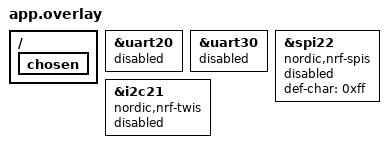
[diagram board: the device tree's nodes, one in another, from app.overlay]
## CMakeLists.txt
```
cmake_minimum_required(VERSION 3.20.0)
find_package(Zephyr REQUIRED HINTS $ENV{ZEPHYR_BASE})
project(r01_serial LANGUAGES C CXX)
target_sources(app PRIVATE src/main.cpp)
```

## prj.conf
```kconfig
CONFIG_ZTEST=y
CONFIG_CPP=y
CONFIG_STD_CPP17=y
CONFIG_CPP_EXCEPTIONS=n
CONFIG_CPP_RTTI=n
CONFIG_ZTEST_NO_YIELD=y
CONFIG_CONSOLE=n
CONFIG_SERIAL=n
CONFIG_PRINTK=n
CONFIG_LOG=n
CONFIG_NUCODE_ARDUINO_CORE=y
CONFIG_NUCODE_ARDUINO_RUNTIME=n
CONFIG_NUCODE_ARDUINO_API=y
CONFIG_NUCODE_ARDUINO_IO_OWNERSHIP=y
CONFIG_NUCODE_ARDUINO_IO_RESOURCE_SLOTS=64
CONFIG_NUCODE_ARDUINO_GPIO=y
CONFIG_NUCODE_ARDUINO_CONNECTOR_GPIO=y
CONFIG_NUCODE_ARDUINO_DAP_UART_GPIO_PINS=y
CONFIG_NUCODE_ARDUINO_INTERRUPTS=n
CONFIG_NUCODE_ARDUINO_TIME=n
CONFIG_NUCODE_ARDUINO_SERIAL=n
CONFIG_NUCODE_ARDUINO_SERIAL_FABRIC=y
CONFIG_NUCODE_ARDUINO_WIRE=n
CONFIG_NUCODE_ARDUINO_SPI=n
CONFIG_NUCODE_ARDUINO_ADC=n
CONFIG_NUCODE_ARDUINO_PWM=n
CONFIG_COMMON_LIBC_MALLOC_ARENA_SIZE=8192
CONFIG_MAIN_STACK_SIZE=4096
CONFIG_TEST_EXTRA_STACK_SIZE=2048
```

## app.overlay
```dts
/** @brief 직접 adapter의 IRQ를 Zephyr device가 소유하지 않는 구성입니다. */
#include <nucode/nu54dk-arduino-pins.dtsi>

/ {
    chosen {
        /delete-property/ zephyr,console;
        /delete-property/ zephyr,shell-uart;
        /delete-property/ zephyr,uart-mcumgr;
        /delete-property/ zephyr,bt-mon-uart;
        /delete-property/ zephyr,bt-c2h-uart;
    };
};

&uart20 { status = "disabled"; };
&uart30 { status = "disabled"; };

/** @brief nrfx의 compatible 조건만 제공하고 device와 IRQ는 비활성으로 유지합니다. */
&spi22 {
    compatible = "nordic,nrf-spis";
    /delete-property/ rx-delay-supported;
    /delete-property/ rx-delay;
    def-char = <0xff>;
    status = "disabled";
};

&i2c21 {
    compatible = "nordic,nrf-twis";
    status = "disabled";
};
```

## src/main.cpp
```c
/**
 * @file main.cpp
 * @brief 선택한 personality의 실제 공개 함수 참조와 링크를 검증합니다.
 * SPDX-License-Identifier: MIT
 */

#include <nucode/SerialFabric.h>
#include <zephyr/ztest.h>

using namespace nucode::arduino;

ZTEST(r01_serial, test_selected_personality_implementations_are_linked)
{
    auto &fabric = serialFabric();
    zassert_not_null(fabric.uarte(21U));
#if defined(CONFIG_NUCODE_ARDUINO_SERIAL_FABRIC_UARTE)
    zassert_equal(fabric.uarte(21U)->configure({115200U, UarteParity::none, false}),
                  SerialFabricResult::success);
#endif
#if defined(CONFIG_NUCODE_ARDUINO_SERIAL_FABRIC_SPIM)
    zassert_equal(fabric.spim(21U)->configure(
                      {4000000U, SpiFabricMode::mode0, SpiFabricBitOrder::msb_first, 0xFFU}),
                  SerialFabricResult::success);
#endif
#if defined(CONFIG_NUCODE_ARDUINO_SERIAL_FABRIC_SPIS)
    zassert_equal(fabric.spis(21U)->configure(
                      {0U, SpiFabricMode::mode0, SpiFabricBitOrder::msb_first, 0xFFU}),
                  SerialFabricResult::success);
#endif
#if defined(CONFIG_NUCODE_ARDUINO_SERIAL_FABRIC_TWIM)
    zassert_equal(fabric.twim(21U)->configure({TwiFabricFrequency::standard}),
                  SerialFabricResult::success);
#endif
#if defined(CONFIG_NUCODE_ARDUINO_SERIAL_FABRIC_TWIS)
    zassert_equal(fabric.twis(21U)->configure({0x42U}), SerialFabricResult::success);
#endif
}

ZTEST_SUITE(r01_serial, nullptr, nullptr, nullptr, nullptr, nullptr);
```
